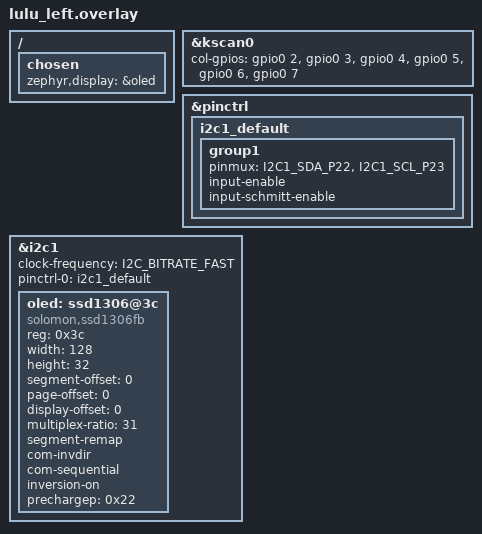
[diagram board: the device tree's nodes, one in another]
/*
 * Copyright (c) 2020 Pete Johanson
 *
 * SPDX-License-Identifier: MIT
 */

#include "lulu.dtsi"

&kscan0 {
    col-gpios
        = <&gpio0  2 GPIO_ACTIVE_HIGH>
        , <&gpio0  3 GPIO_ACTIVE_HIGH>
        , <&gpio0  4 GPIO_ACTIVE_HIGH>
        , <&gpio0  5 GPIO_ACTIVE_HIGH>
        , <&gpio0  6 GPIO_ACTIVE_HIGH>
        , <&gpio0  7 GPIO_ACTIVE_HIGH>
        ;
};

/ {
    chosen {
        zephyr,display = &oled;
    };
};

&pinctrl {
    i2c1_default: i2c1_default {
        group1 {
            pinmux = <I2C1_SDA_P22>, <I2C1_SCL_P23>;
            input-enable;
            input-schmitt-enable;
        };
    };
};

&i2c1 {
    status = "okay";
    clock-frequency = <I2C_BITRATE_FAST>;
    pinctrl-0 = <&i2c1_default>;
    pinctrl-names = "default";

    oled: ssd1306@3c {
        compatible = "solomon,ssd1306fb";
        reg = <0x3c>;
        width = <128>;
        height = <32>;
        segment-offset = <0>;
        page-offset = <0>;
        display-offset = <0>;
        multiplex-ratio = <31>;
        segment-remap;
        com-invdir;
        com-sequential;
        inversion-on;
        prechargep = <0x22>;
    };
};
